# M55M1 register map
File version: 1.0
Registers are 32-bit, read-write, reset 0x0 unless marked. A register's access mark holds for its fields unless they carry their own. Offsets are from the block's base; [hi:lo] are bit positions; {n}, {i} and the like mark numbered series.

## UART0 (part 1 of 2) — UART Register Map
Base 0x4024D000
Same registers: UART1 0x4028D000, UART0_NS 0x5024D000, UART1_NS 0x5028D000
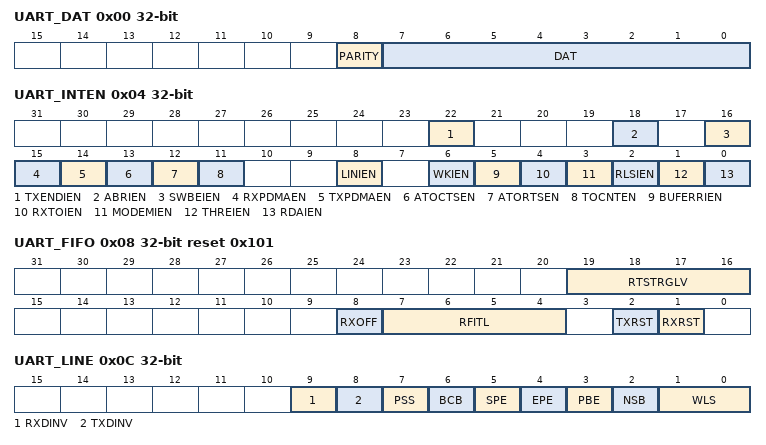
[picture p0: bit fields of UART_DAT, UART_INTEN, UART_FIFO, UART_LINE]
0x00 UART_DAT reset not defined — UART Receive/Transmit Buffer Register
  [8] PARITY — PARITY Bit Receive/Transmit Buffer. Write Operation: By writing to this bit, the PARITY bit will be stored in transmitter FIFO. If PBE (UART_LINE[3]) and PSS (UART_LINE[7]) are set, the UART controller will send out this bit follow the DAT (UART_DAT[7:0]) through the UART_TXD. Read Operation: If PBE (UART_LINE[3]) and PSS (UART_LINE[7]) are enabled, the PARITY bit can be read by this bit. Note: This bit has effect only when PBE (UART_LINE[3]) and PSS (UART_LINE[7]) are set.
  [7:0] DAT — Data Receive/Transmit Buffer. Write Operation: By writing one byte to this register, the data byte will be stored in transmitter FIFO. The UART controller will send out the data stored in transmitter FIFO top location through the UART_TXD. Read Operation: By reading this register, the UART controller will return an 8-bit data received from receiver FIFO.
0x04 UART_INTEN — UART Interrupt Enable Register
  [22] TXENDIEN — Transmitter Empty Interrupt Enable Bit. If TXENDIEN (UART_INTEN[22]) is enabled, the Transmitter Empty interrupt TXENDINT (UART_INTSTS[30]) will be generated when TXENDIF (UART_INTSTS[22]) is set (TX FIFO (UART_DAT) is empty and the STOP bit of the last byte has been transmitted).
    0=Transmitter empty interrupt Disabled; 1=Transmitter empty interrupt Enabled
  [18] ABRIEN — Auto-baud Rate Interrupt Enable Bit
    0=Auto-baud rate interrupt Disabled; 1=Auto-baud rate interrupt Enabled
  [16] SWBEIEN — Single-wire Bit Error Detection Interrupt Enable Bit. Set this bit, the Single-wire Half Duplex Bit Error Detection Interrupt SWBEINT(UART_INTSTS[24]) is generated when Single-wire Bit Error Detection SWBEIF(UART_INTSTS[16]) is set. Note: This bit is valid when FUNCSEL (UART_FUNCSEL[2:0]) is select UART Single-wire mode.
    0=Single-wire Bit Error Detect Interrupt Disabled; 1=Single-wire Bit Error Detect Interrupt Enabled
  [15] RXPDMAEN — RX PDMA Enable Bit. This bit can enable or disable RX PDMA service. Note: If RLSIEN (UART_INTEN[2]) is enabled and HWRLSINT (UART_INTSTS[26]) is set to 1, the RLS (Receive Line Status) Interrupt is caused. If RLS interrupt is caused by Break Error Flag BIF(UART_FIFOSTS[6]), Frame Error Flag FEF(UART_FIFO[5]) or Parity Error Flag PEF(UART_FIFOSTS[4]), UART PDMA receive request operation is stopped. Clear Break Error Flag BIF or Frame Error Flag FEF or Parity Error Flag PEF by writing '1' to corresponding BIF, FEF and PEF to make UART PDMA receive request operation continue.
    0=RX PDMA Disabled; 1=RX PDMA Enabled
  [14] TXPDMAEN — TX PDMA Enable Bit. Note: If RLSIEN (UART_INTEN[2]) is enabled and HWRLSINT (UART_INTSTS[26]) is set to 1, the RLS (Receive Line Status) Interrupt is caused. If RLS interrupt is caused by Break Error Flag BIF(UART_FIFOSTS[6]), Frame Error Flag FEF(UART_FIFO[5]) or Parity Error Flag PEF(UART_FIFOSTS[4]), UART PDMA transmit request operation is stopped. Clear Break Error Flag BIF or Frame Error Flag FEF or Parity Error Flag PEF by writing '1' to corresponding BIF, FEF and PEF to make UART PDMA transmit request operation continue.
    0=TX PDMA Disabled; 1=TX PDMA Enabled
  [13] ATOCTSEN — nCTS Auto-flow Control Enable Bit. Note: When nCTS auto-flow is enabled, the UART will send data to external device if nCTS input assert (UART will not send data to device until nCTS is asserted).
    0=nCTS auto-flow control Disabled; 1=nCTS auto-flow control Enabled
  [12] ATORTSEN — nRTS Auto-flow Control Enable Bit. Note: When nRTS auto-flow is enabled, if the number of bytes in the RX FIFO equals the RTSTRGLV (UART_FIFO[19:16]), the UART will de-assert nRTS signal.
    0=nRTS auto-flow control Disabled; 1=nRTS auto-flow control Enabled
  [11] TOCNTEN — Receive Buffer Time-out Counter Enable Bit
    0=Receive Buffer Time-out counter Disabled; 1=Receive Buffer Time-out counter Enabled
  [8] LINIEN — LIN Bus Interrupt Enable Bit. Note: This bit is used for LIN function mode.
    0=LIN bus interrupt Disabled; 1=LIN bus interrupt Enabled
  [6] WKIEN — Wake-up Interrupt Enable Bit
    0=Wake-up Interrupt Disabled; 1=Wake-up Interrupt Enabled
  [5] BUFERRIEN — Buffer Error Interrupt Enable Bit
    0=Buffer error interrupt Disabled; 1=Buffer error interrupt Enabled
  [4] RXTOIEN — RX Time-out Interrupt Enable Bit
    0=RX time-out interrupt Disabled; 1=RX time-out interrupt Enabled
  [3] MODEMIEN — Modem Status Interrupt Enable Bit
    0=Modem status interrupt Disabled; 1=Modem status interrupt Enabled
  [2] RLSIEN — Receive Line Status Interrupt Enable Bit
    0=Receive Line Status interrupt Disabled; 1=Receive Line Status interrupt Enabled
  [1] THREIEN — Transmit Holding Register Empty Interrupt Enable Bit
    0=Transmit holding register empty interrupt Disabled; 1=Transmit holding register empty interrupt Enabled
  [0] RDAIEN — Receive Data Available Interrupt Enable Bit
    0=Receive data available interrupt Disabled; 1=Receive data available interrupt Enabled
0x08 UART_FIFO reset 0x101 — UART FIFO Control Register
  [19:16] RTSTRGLV — nRTS Trigger Level for Auto-flow Control. Note: This field is used for auto nRTS flow control.
    0=nRTS Trigger Level is 1 byte; 1=nRTS Trigger Level is 4 bytes; 2=nRTS Trigger Level is 8 bytes; 3=nRTS Trigger Level is 14 bytes
  [8] RXOFF — Receiver Disable Bit. The receiver is disabled or not (set 1 to disable receiver). Note: This bit is used for RS-485 Normal Multi-drop mode. It should be programmed before RS485NMM (UART_ALTCTL[8]) is programmed.
    0=Receiver Enabled; 1=Receiver Disabled
  [7:4] RFITL — RX FIFO Interrupt Trigger Level. When the number of bytes in the receive FIFO equals the RFITL, the RDAIF (UART_INTSTS[0]) will be set (if RDAIEN (UART_INTEN[0]) enabled, and an interrupt will be generated).
    0=RX FIFO Interrupt Trigger Level is 1 byte; 1=RX FIFO Interrupt Trigger Level is 4 bytes; 2=RX FIFO Interrupt Trigger Level is 8 bytes; 3=RX FIFO Interrupt Trigger Level is 14 bytes
  [2] TXRST — TX Field Software Reset. When TXRST (UART_FIFO[2]) is set, all the byte in the transmit FIFO and TX internal state machine are cleared. Note 1: This bit will automatically clear at least 3 UART peripheral clock cycles. Note 2: Before setting this bit, it should wait for the TXEMPTYF (UART_FIFOSTS[28]) be set.
    0=No effect; 1=Reset the TX internal state machine and pointers
  [1] RXRST — RX Field Software Reset. When RXRST (UART_FIFO[1]) is set, all the byte in the receiver FIFO and RX internal state machine are cleared. Note 1: This bit will automatically clear at least 3 UART peripheral clock cycles. Note 2: Before setting this bit, it should wait for the RXIDLE (UART_FIFOSTS[29]) be set.
    0=No effect; 1=Reset the RX internal state machine and pointers
0x0C UART_LINE — UART Line Control Register
  [9] RXDINV — RX Data Inverted. Note 1: Before setting this bit, TXRXDIS (UART_FUNCSEL[3]) should be set then waited for TXRXACT (UART_FIFOSTS[31]) is cleared. When the configuration is done, cleared TXRXDIS (UART_FUNCSEL[3]) to activate UART controller. Note 2: This bit is valid when FUNCSEL (UART_FUNCSEL[2:0]) is select UART, LIN or RS485 function.
    0=Received data signal inverted Disabled; 1=Received data signal inverted Enabled
  [8] TXDINV — TX Data Inverted. Note 1: Before setting this bit, TXRXDIS (UART_FUNCSEL[3]) should be set then waited for TXRXACT (UART_FIFOSTS[31]) is cleared. When the configuration is done, cleared TXRXDIS (UART_FUNCSEL[3]) to activate UART controller. Note 2: This bit is valid when FUNCSEL (UART_FUNCSEL[2:0]) is select UART, LIN or RS485 function.
    0=Transmitted data signal inverted Disabled; 1=Transmitted data signal inverted Enabled
  [7] PSS — PARITY Bit Source Selection. The PARITY bit can be selected to be generated and checked automatically or by software. Note 1: This bit has effect only when PBE (UART_LINE[3]) is set. Note 2: If PSS is 0, the PARITY bit is transmitted and checked automatically. If PSS is 1, the transmitted PARITY bit value can be determined by writing PARITY (UART_DAT[8]) and the PARITY bit can be read by reading PARITY (UART_DAT[8]).
    0=PARITY bit is generated by EPE (UART_LINE[4]) and SPE (UART_LINE[5]) setting and checked automatically; 1=PARITY bit generated and checked by software
  [6] BCB — Break Control Bit. Note: When this bit is set to logic 1, the transmitted serial data output (TX) is forced to the Spacing State (logic 0). This bit acts only on TX line and has no effect on the transmitter logic.
    0=Break Control Disabled; 1=Break Control Enabled
  [5] SPE — Stick Parity Enable Bit. Note: If PBE (UART_LINE[3]) and EPE (UART_LINE[4]) are logic 1, the PARITY bit is transmitted and checked as logic 0. If PBE (UART_LINE[3]) is 1 and EPE (UART_LINE[4]) is 0 then the PARITY bit is transmitted and checked as 1.
    0=Stick parity Disabled; 1=Stick parity Enabled
  [4] EPE — Even Parity Enable Bit. Note: This bit has effect only when PBE (UART_LINE[3]) is set.
    0=Odd number of logic 1's is transmitted and checked in each word; 1=Even number of logic 1's is transmitted and checked in each word
  [3] PBE — PARITY Bit Enable Bit. Note: PARITY bit is generated on each outgoing character and is checked on each incoming data.
    0=PARITY bit generated Disabled; 1=PARITY bit generated Enabled
  [2] NSB — Number of 'STOP Bit'
    0=One 'STOP bit' is generated in the transmitted data; 1=When select 5-bit word length, 1.5 'STOP bit' is generated in the transmitted data. When select 6-, 7- and 8-bit word length, 2 'STOP bit' is generated in the transmitted data
  [1:0] WLS — Word Length Selection. This field sets UART word length.
    {v}={v+5} bits (v=0..3)
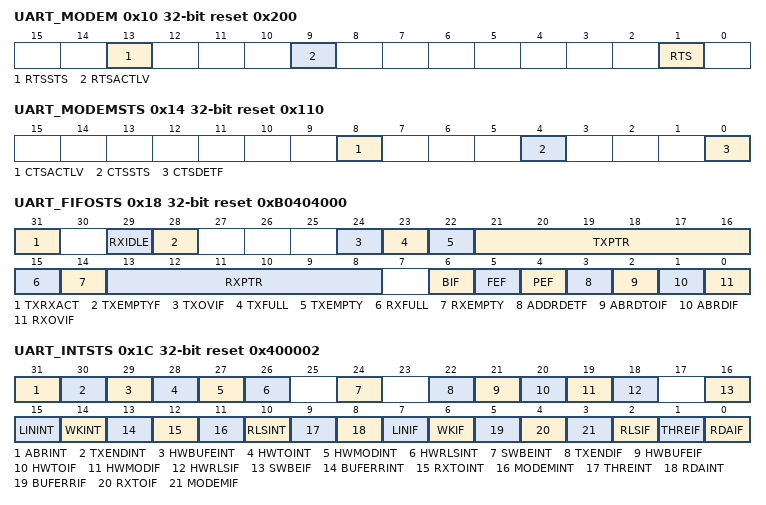
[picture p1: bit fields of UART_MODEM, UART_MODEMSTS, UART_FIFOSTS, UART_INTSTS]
0x10 UART_MODEM reset 0x200 — UART Modem Control Register
  [13] RTSSTS ro — nRTS Pin Status (Read Only). This bit mirror from nRTS pin output of voltage logic status.
    0=nRTS pin output is low level voltage logic state; 1=nRTS pin output is high level voltage logic state
  [9] RTSACTLV — nRTS Pin Active Level. This bit defines the active level state of nRTS pin output. Note 1: Refer to Figure 6.2613 and Figure 6.2614 for UART function mode. Note 2: Refer to Figure 6.2624 and Figure 6.2625 for RS-485 function mode. Note 3: Before setting this bit, TXRXDIS (UART_FUNCSEL[3]) should be set then waited for TXRXACT (UART_FIFOSTS[31]) is cleared. When the configuration is done, cleared TXRXDIS (UART_FUNCSEL[3]) to activate UART controller.
    0=nRTS pin output is high level active; 1=nRTS pin output is low level active. (Default)
  [1] RTS — nRTS Signal Control. This bit is direct control internal nRTS (Request-to-send) signal active or not, and then drive the nRTS pin output with RTSACTLV bit configuration. Note 1: The nRTS signal control bit is not effective when nRTS auto-flow control is enabled in UART function mode. Note 2: The nRTS signal control bit is not effective when RS-485 auto direction mode (AUD) is enabled in RS-485 function mode. Note 3: Single-wire mode is support this feature.
    0=nRTS signal is active; 1=nRTS signal is inactive
0x14 UART_MODEMSTS reset 0x110 — UART Modem Status Register
  [8] CTSACTLV — nCTS Pin Active Level. This bit defines the active level state of nCTS pin input. Note: Before setting this bit, TXRXDIS (UART_FUNCSEL[3]) should be set then waited for TXRXACT (UART_FIFOSTS[31]) is cleared. When the configuration is done, cleared TXRXDIS (UART_FUNCSEL[3]) to activate UART controller.
    0=nCTS pin input is high level active; 1=nCTS pin input is low level active. (Default)
  [4] CTSSTS ro — nCTS Pin Status (Read Only). This bit mirror from nCTS pin input of voltage logic status. Note: This bit echoes when UART controller peripheral clock is enabled, and nCTS multi-function port is selected.
    0=nCTS pin input is low level voltage logic state; 1=nCTS pin input is high level voltage logic state
  [0] CTSDETF — Detect nCTS State Change Flag. This bit is set whenever nCTS input has change state, and it will generate Modem interrupt to CPU when MODEMIEN (UART_INTEN[3]) is set to 1. Note: This bit can be cleared by writing '1' to it.
    0=nCTS input has not change state; 1=nCTS input has change state
0x18 UART_FIFOSTS reset 0xB0404000 — UART FIFO Status Register
  [31] TXRXACT ro — TX and RX Active Status (Read Only). This bit indicates TX and RX are active or inactive. Note: When TXRXDIS (UART_FUNCSEL[3]) is set and both TX and RX are in idle state, this bit is cleared. The UART controller cannot transmit or receive data at this moment. Otherwise this bit is set.
    0=TX and RX are inactive; 1=TX and RX are active. (Default)
  [29] RXIDLE ro — RX Idle Status (Read Only). This bit is set by hardware when RX is idle.
    0=RX is busy; 1=RX is idle. (Default)
  [28] TXEMPTYF ro — Transmitter Empty Flag (Read Only). This bit is set by hardware when TX FIFO (UART_DAT) is empty and the STOP bit of the last byte has been transmitted. Note: This bit is cleared automatically when TX FIFO is not empty or the last byte transmission has not completed.
    0=TX FIFO is not empty or the STOP bit of the last byte has been not transmitted; 1=TX FIFO is empty and the STOP bit of the last byte has been transmitted
  [24] TXOVIF — TX Overflow Error Interrupt Flag. If TX FIFO (UART_DAT) is full, an additional write to UART_DAT will cause this bit to logic 1. Note: This bit can be cleared by writing '1' to it.
    0=TX FIFO is not overflow; 1=TX FIFO is overflow
  [23] TXFULL ro — Transmitter FIFO Full (Read Only). This bit indicates TX FIFO full or not. Note: This bit is set when the number of usage in TX FIFO Buffer is equal to 16, otherwise it is cleared by hardware.
    0=TX FIFO is not full; 1=TX FIFO is full
  [22] TXEMPTY ro — Transmitter FIFO Empty (Read Only). This bit indicates TX FIFO empty or not. Note: When the last byte of TX FIFO has been transferred to Transmitter Shift Register, hardware sets this bit high. It will be cleared when writing data into UART_DAT (TX FIFO not empty).
    0=TX FIFO is not empty; 1=TX FIFO is empty
  [21:16] TXPTR ro — TX FIFO Pointer (Read Only). This field indicates the TX FIFO Buffer Pointer. When CPU writes one byte into UART_DAT, TXPTR increases one. When one byte of TX FIFO is transferred to Transmitter Shift Register, TXPTR decreases one. The Maximum value shown in TXPTR is 15. When the using level of TX FIFO Buffer equal to 16, the TXFULL bit is set to 1 and TXPTR will show 0. As one byte of TX FIFO is transferred to Transmitter Shift Register, the TXFULL bit is cleared to 0 and TXPTR will show 15.
  [15] RXFULL ro — Receiver FIFO Full (Read Only). This bit initiates RX FIFO full or not. Note: This bit is set when the number of usage in RX FIFO Buffer is equal to 16, otherwise it is cleared by hardware.
    0=RX FIFO is not full; 1=RX FIFO is full
  [14] RXEMPTY ro — Receiver FIFO Empty (Read Only). This bit initiate RX FIFO empty or not. Note: When the last byte of RX FIFO has been read by CPU, hardware sets this bit high. It will be cleared when UART receives any new data.
    0=RX FIFO is not empty; 1=RX FIFO is empty
  [13:8] RXPTR ro — RX FIFO Pointer (Read Only). This field indicates the RX FIFO Buffer Pointer. When UART receives one byte from external device, RXPTR increases one. When one byte of RX FIFO is read by CPU, RXPTR decreases one. The Maximum value shown in RXPTR is 15. When the using level of RX FIFO Buffer equal to 16, the RXFULL bit is set to 1 and RXPTR will show 0. As one byte of RX FIFO is read by CPU, the RXFULL bit is cleared to 0 and RXPTR will show 15.
  [6] BIF — Break Interrupt Flag. This bit is set to logic 1 whenever the received data input (RX) is held in the 'spacing state' (logic 0) for longer than a full word transmission time (that is, the total time of 'START bit' + data bits + parity + STOP bits). Note: This bit can be cleared by writing '1' to it.
    0=No Break interrupt is generated; 1=Break interrupt is generated
  [5] FEF — Framing Error Flag. This bit is set to logic 1 whenever the received character does not have a valid 'STOP bit' (that is, the STOP bit following the last data bit or PARITY bit is detected as logic 0). Note: This bit can be cleared by writing '1' to it.
    0=No framing error is generated; 1=Framing error is generated
  [4] PEF — Parity Error Flag. This bit is set to logic 1 whenever the received character does not have a valid 'PARITY bit'. Note: This bit can be cleared by writing '1' to it.
    0=No parity error is generated; 1=Parity error is generated
  [3] ADDRDETF — RS-485 Address Byte Detect Flag. Note 1: This field is used for RS-485 function mode and ADDRDEN (UART_ALTCTL[15]) is set to 1 to enable Address detection mode. Note 2: This bit can be cleared by writing '1' to it.
    0=Receiver detects a data that is not an address bit (bit 9 ='0'); 1=Receiver detects a data that is an address bit (bit 9 ='1')
  [2] ABRDTOIF — Auto-baud Rate Detect Time-out Interrupt Flag. This bit is set to logic '1' in Auto-baud Rate Detect mode when the baud rate counter is overflow. Note: This bit can be cleared by writing '1' to it.
    0=Auto-baud rate counter is underflow; 1=Auto-baud rate counter is overflow
  [1] ABRDIF — Auto-baud Rate Detect Interrupt Flag. This bit is set to logic '1' when auto-baud rate detect function is finished. Note: This bit can be cleared by writing '1' to it.
    0=Auto-baud rate detect function is not finished; 1=Auto-baud rate detect function is finished
  [0] RXOVIF — RX Overflow Error Interrupt Flag. This bit is set when RX FIFO overflow. If the number of bytes of received data is greater than RX_FIFO (UART_DAT) size 16 bytes, this bit will be set. Note: This bit can be cleared by writing '1' to it.
    0=RX FIFO is not overflow; 1=RX FIFO is overflow
0x1C UART_INTSTS reset 0x400002 — UART Interrupt Status Register
  [31] ABRINT ro — Auto-baud Rate Interrupt Indicator (Read Only). This bit is set if ABRIEN (UART_INTEN[18]) and ABRIF (UART_ALTCTL[17]) are both set to 1.
    0=No Auto-baud Rate interrupt is generated; 1=The Auto-baud Rate interrupt is generated
  [30] TXENDINT ro — Transmitter Empty Interrupt Indicator (Read Only). This bit is set if TXENDIEN (UART_INTEN[22]) and TXENDIF(UART_INTSTS[22]) are both set to 1.
    0=No Transmitter Empty interrupt is generated; 1=Transmitter Empty interrupt is generated
  [29] HWBUFEINT ro — PDMA Mode Buffer Error Interrupt Indicator (Read Only). This bit is set if BUFERRIEN (UART_INTEN[5]) and HWBUFEIF (UART_INTSTS[21]) are both set to 1.
    0=No buffer error interrupt is generated when RXPDMAEN (UART_INTEN[15]) or TXPDMAEN (UART_INTEN[14]) is 1; 1=Buffer error interrupt is generated when RXPDMAEN (UART_INTEN[15]) or TXPDMAEN (UART_INTEN[14]) is 1
  [28] HWTOINT ro — PDMA Mode RX Time-out Interrupt Indicator (Read Only). This bit is set if RXTOIEN (UART_INTEN[4]) and HWTOIF(UART_INTSTS[20]) are both set to 1.
    0=No RX time-out interrupt is generated when RXPDMAEN (UART_INTEN[15]) or TXPDMAEN (UART_INTEN[14]) is 1; 1=RX time-out interrupt is generated when RXPDMAEN (UART_INTEN[15]) or TXPDMAEN (UART_INTEN[14]) is 1
  [27] HWMODINT ro — PDMA Mode MODEM Status Interrupt Indicator (Read Only). This bit is set if MODEMIEN (UART_INTEN[3]) and HWMODIF(UART_INTSTS[19]) are both set to 1.
    0=No Modem interrupt is generated when RXPDMAEN (UART_INTEN[15]) or TXPDMAEN (UART_INTEN[14]) is 1; 1=Modem interrupt is generated when RXPDMAEN (UART_INTEN[15]) or TXPDMAEN (UART_INTEN[14]) is 1
  [26] HWRLSINT ro — PDMA Mode Receive Line Status Interrupt Indicator (Read Only). This bit is set if RLSIEN (UART_INTEN[2]) and HWRLSIF(UART_INTSTS[18]) are both set to 1.
    0=No RLS interrupt is generated when RXPDMAEN (UART_INTEN[15]) or TXPDMAEN (UART_INTEN[14]) is 1; 1=RLS interrupt is generated when RXPDMAEN (UART_INTEN[15]) or TXPDMAEN (UART_INTEN[14]) is 1
  [24] SWBEINT ro — Single-wire Bit Error Detect Interrupt Indicator (Read Only). This bit is set if SWBEIEN (UART_INTEN[16]) and SWBEIF (UART_INTSTS[16]) are both set to 1.
    0=No Single-wire Bit Error Detection Interrupt generated; 1=Single-wire Bit Error Detection Interrupt generated
  [22] TXENDIF — Transmitter Empty Interrupt Flag. This bit is set when TX FIFO (UART_DAT) is empty and the STOP bit of the last byte has been transmitted (TXEMPTYF (UART_FIFOSTS[28]) is set). If TXENDIEN (UART_INTEN[22]) is enabled, the Transmitter Empty interrupt will be generated. Note: This bit is cleared automatically when TX FIFO is not empty or the last byte transmission has not completed.
    0=No transmitter empty interrupt flag is generated; 1=Transmitter empty interrupt flag is generated
  [21] HWBUFEIF ro — PDMA Mode Buffer Error Interrupt Flag (Read Only). This bit is set when the TX or RX FIFO overflows (TXOVIF (UART_FIFOSTS[24]) or RXOVIF (UART_FIFOSTS[0]) is set). When BUFERRIF (UART_INTSTS[5]) is set, the transfer maybe is not correct. If BUFERRIEN (UART_INTEN[5]) is enabled, the buffer error interrupt will be generated. Note: This bit is cleared when both TXOVIF (UART_FIFOSTS[24]]) and RXOVIF (UART_FIFOSTS[0]) are cleared.
    0=No buffer error interrupt flag is generated when RXPDMAEN (UART_INTEN[15]) or TXPDMAEN (UART_INTEN[14]) is 1; 1=Buffer error interrupt flag is generated when RXPDMAEN (UART_INTEN[15]) or TXPDMAEN (UART_INTEN[14]) is 1
  [20] HWTOIF ro — PDMA Mode RX Time-out Interrupt Flag (Read Only). This bit is set when the RX FIFO is not empty and no activities occurred in the RX FIFO and the time-out counter equal to TOIC (UART_TOUT[7:0]). If RXTOIEN (UART_INTEN[4]) is enabled, the RX time-out interrupt will be generated. Note: This bit is read only and user can read UART_DAT (RX is in active) to clear it.
    0=No RX time-out interrupt flag is generated when RXPDMAEN (UART_INTEN[15]) or TXPDMAEN (UART_INTEN[14]) is 1; 1=RX time-out interrupt flag is generated when RXPDMAEN (UART_INTEN[15]) or TXPDMAEN (UART_INTEN[14]) is 1
  [19] HWMODIF ro — PDMA Mode MODEM Interrupt Flag (Read Only). Note: This bit is read only and reset to 0 when the bit CTSDETF (UART_MODEMSTS[0]) is cleared by writing 1 on CTSDETF (UART_MODEMSTS[0]).
    0=No Modem interrupt flag is generated when RXPDMAEN (UART_INTEN[15]) or TXPDMAEN (UART_INTEN[14]) is 1; 1=Modem interrupt flag is generated when RXPDMAEN (UART_INTEN[15]) or TXPDMAEN (UART_INTEN[14]) is 1
  [18] HWRLSIF ro — PDMA Mode Receive Line Status Flag (Read Only). This bit is set when the RX receive data have parity error, frame error or break error (at least one of 3 bits, BIF (UART_FIFOSTS[6]), FEF (UART_FIFOSTS[5]) and PEF (UART_FIFOSTS[4]) is set). If RLSIEN (UART_INTEN[2]) is enabled, the RLS interrupt will be generated. Note 2: In UART function mode, this bit is read only and reset to 0 when all bits of BIF(UART_FIFOSTS[6]), FEF(UART_FIFOSTS[5]) and PEF(UART_FIFOSTS[4]) are cleared. Note 3: In RS-485 function mode, this bit is read only and reset to 0 when all bits of BIF(UART_FIFOSTS[6]), FEF(UART_FIFOSTS[5]), PEF(UART_FIFOSTS[4]) and ADDRDETF (UART_FIFOSTS[3]) are cleared.
    0=No RLS interrupt flag is generated when RXPDMAEN (UART_INTEN[15]) or TXPDMAEN (UART_INTEN[14]) is 1; 1=RLS interrupt flag is generated when RXPDMAEN (UART_INTEN[15]) or TXPDMAEN (UART_INTEN[14]) is 1
  [16] SWBEIF — Single-wire Bit Error Detection Interrupt Flag. This bit is set when the single wire bus state not equals to UART controller TX state in Single-wire mode. Note 1: This bit is active when FUNCSEL (UART_FUNCSEL[2:0]) is select UART Single-wire mode. Note 2: This bit can be cleared by writing '1' to it.
    0=No single-wire bit error detection interrupt flag is generated; 1=Single-wire bit error detection interrupt flag is generated
  [15] LININT ro — LIN Bus Interrupt Indicator (Read Only). This bit is set if LINIEN (UART_INTEN[8]) and LINIF(UART_INTSTS[7]) are both set to 1.
    0=No LIN Bus interrupt is generated; 1=The LIN Bus interrupt is generated
  [14] WKINT ro — UART Wake-up Interrupt Indicator (Read Only). This bit is set if WKIEN (UART_INTEN[6]) and WKIF (UART_INTSTS[6]) are both set to 1.
    0=No UART wake-up interrupt is generated; 1=UART wake-up interrupt is generated
  [13] BUFERRINT ro — Buffer Error Interrupt Indicator (Read Only). This bit is set if BUFERRIEN(UART_INTEN[5]) and BUFERRIF(UART_ INTSTS[5]) are both set to 1. Note: This bit is valid only when RXPDMAEN (UART_INTEN[15]) and TXPDMAEN (UART_INTEN[14]) are both 0.
    0=No buffer error interrupt is generated; 1=Buffer error interrupt is generated
  [12] RXTOINT ro — RX Time-out Interrupt Indicator (Read Only). This bit is set if RXTOIEN (UART_INTEN[4]) and RXTOIF(UART_INTSTS[4]) are both set to 1. Note: This bit is valid only when RXPDMAEN (UART_INTEN[15]) and TXPDMAEN (UART_INTEN[14]) are both 0.
    0=No RX time-out interrupt is generated; 1=RX time-out interrupt is generated
  [11] MODEMINT ro — MODEM Status Interrupt Indicator (Read Only). This bit is set if MODEMIEN(UART_INTEN[3]) and MODEMIF(UART_INTSTS[3]) are both set to 1. Note: This bit is valid only when RXPDMAEN (UART_INTEN[15]) and TXPDMAEN (UART_INTEN[14]) are both 0.
    0=No Modem interrupt is generated; 1=Modem interrupt is generated
  [10] RLSINT ro — Receive Line Status Interrupt Indicator (Read Only). This bit is set if RLSIEN (UART_INTEN[2]) and RLSIF(UART_INTSTS[2]) are both set to 1. Note: This bit is valid only when RXPDMAEN (UART_INTEN[15]) and TXPDMAEN (UART_INTEN[14]) are both 0.
    0=No RLS interrupt is generated; 1=RLS interrupt is generated
  [9] THREINT ro — Transmit Holding Register Empty Interrupt Indicator (Read Only). This bit is set if THREIEN (UART_INTEN[1]) and THREIF(UART_INTSTS[1]) are both set to 1.
    0=No THRE interrupt is generated; 1=THRE interrupt is generated
  [8] RDAINT ro — Receive Data Available Interrupt Indicator (Read Only). This bit is set if RDAIEN (UART_INTEN[0]) and RDAIF (UART_INTSTS[0]) are both set to 1.
    0=No RDA interrupt is generated; 1=RDA interrupt is generated
  [7] LINIF — LIN Bus Interrupt Flag. Note: This bit is cleared when SLVHDETF(UART_LINSTS[0]), BRKDETF(UART_LINSTS[8]), BITEF(UART_LINSTS[9]), SLVIDPEF (UART_LINSTS[2]) and SLVHEF(UART_LINSTS[1]) all are cleared and software writing '1' to LINIF(UART_INTSTS[7]).
    0=None of SLVHDETF, BRKDETF, BITEF, SLVIDPEF and SLVHEF is generated; 1=At least one of SLVHDETF, BRKDETF, BITEF, SLVIDPEF and SLVHEF is generated
  [6] WKIF ro — UART Wake-up Interrupt Flag (Read Only). This bit is set when TOUTWKF (UART_WKSTS[4]), RS485WKF (UART_WKSTS[3]), RFRTWKF (UART_WKSTS[2]), DATWKF (UART_WKSTS[1]) or CTSWKF(UART_WKSTS[0]) is set to 1. Note: This bit is cleared if all of TOUTWKF, RS485WKF, RFRTWKF, DATWKF and CTSWKF are cleared to 0 by writing 1 to the corresponding interrupt flag.
    0=No UART wake-up interrupt flag is generated; 1=UART wake-up interrupt flag is generated
  [5] BUFERRIF ro — Buffer Error Interrupt Flag (Read Only). This bit is set when the TX FIFO or RX FIFO overflows (TXOVIF (UART_FIFOSTS[24]) or RXOVIF (UART_FIFOSTS[0]) is set). When BUFERRIF (UART_INTSTS[5]) is set, the transfer is not correct. If BUFERRIEN (UART_INTEN[5]) is enabled, the buffer error interrupt will be generated. Note 1: This bit is cleared if both of RXOVIF(UART_FIFOSTS[0]) and TXOVIF(UART_FIFOSTS[24]) are cleared to 0 by writing 1 to RXOVIF(UART_FIFOSTS[0]) and TXOVIF(UART_FIFOSTS[24]). Note 2: This bit is valid only when RXPDMAEN (UART_INTEN[15]) and TXPDMAEN (UART_INTEN[14]) are both 0.
    0=No buffer error interrupt flag is generated; 1=Buffer error interrupt flag is generated
  [4] RXTOIF ro — RX Time-out Interrupt Flag (Read Only). This bit is set when the RX FIFO is not empty and no activities occurred in the RX FIFO and the time-out counter equal to TOIC (UART_TOUT[7:0]). If RXTOIEN (UART_INTEN[4]) is enabled, the RX time-out interrupt will be generated. Note 1: This bit is read only and user can read UART_DAT (RX is in active) to clear it. Note 2: This bit is valid only when RXPDMAEN (UART_INTEN[15]) and TXPDMAEN (UART_INTEN[14]) are both 0.
    0=No RX time-out interrupt flag is generated; 1=RX time-out interrupt flag is generated
  [3] MODEMIF ro — MODEM Interrupt Flag (Read Only). Note 1: This bit is read only and reset to 0 when bit CTSDETF is cleared by a write 1 on CTSDETF(UART_MODEMSTS[0]). Note 2: This bit is valid only when RXPDMAEN (UART_INTEN[15]) and TXPDMAEN (UART_INTEN[14]) are both 0.
    0=No Modem interrupt flag is generated; 1=Modem interrupt flag is generated
  [2] RLSIF ro — Receive Line Interrupt Flag (Read Only). This bit is set when the RX receive data have parity error, frame error or break error (at least one of 3 bits, BIF(UART_FIFOSTS[6]), FEF(UART_FIFOSTS[5]) and PEF(UART_FIFOSTS[4]), is set). If RLSIEN (UART_INTEN[2]) is enabled, the RLS interrupt will be generated. Note 2: This bit is read only and reset to 0 when all bits of BIF (UART_FIFOSTS[6]), FEF(UART_FIFOSTS[5]) and PEF(UART_FIFOSTS[4]) are cleared. Note 3: In RS-485 function mode, this bit is read only and reset to 0 when all bits of BIF (UART_FIFOSTS[6]), FEF(UART_FIFOSTS[5]), PEF(UART_FIFOSTS[4]) and ADDRDETF (UART_FIFOSTS[3]) are cleared. Note 4: This bit is valid only when RXPDMAEN (UART_INTEN[15]) and TXPDMAEN (UART_INTEN[14]) are both 0.
    0=No RLS interrupt flag is generated; 1=RLS interrupt flag is generated
  [1] THREIF ro — Transmit Holding Register Empty Interrupt Flag (Read Only). This bit is set when the last data of TX FIFO is transferred to Transmitter Shift Register. If THREIEN (UART_INTEN[1]) is enabled, the THRE interrupt will be generated. Note: This bit is read only and will be cleared when writing data into UART_DAT (TX FIFO is not empty).
    0=No THRE interrupt flag is generated; 1=THRE interrupt flag is generated
  [0] RDAIF ro — Receive Data Available Interrupt Flag (Read Only). When the number of bytes in the RX FIFO equals the RFITL then the RDAIF(UART_INTSTS[0]) will be set. If RDAIEN (UART_INTEN[0]) is enabled, the RDA interrupt will be generated. Note: This bit is read only and will be cleared when the number of unread bytes of RX FIFO drops below the threshold level (RFITL(UART_FIFO[7:4]).
    0=No RDA interrupt flag is generated; 1=RDA interrupt flag is generated

## UART2 (part 1 of 2) — UART Register Map
Base 0x4024E000
Registers as UART0.

## UART4 (part 1 of 2) — UART Register Map
Base 0x4024F000
Registers as UART0.

## UART6 (part 1 of 2) — UART Register Map
Base 0x40250000
Registers as UART0.

## UART8 (part 1 of 2) — UART Register Map
Base 0x40251000
Registers as UART0.

## UART3 (part 1 of 2) — UART Register Map
Base 0x4028E000
Registers as UART0.

## UART5 (part 1 of 2) — UART Register Map
Base 0x4028F000
Registers as UART0.

## UART7 (part 1 of 2) — UART Register Map
Base 0x40290000
Registers as UART0.

## UART9 (part 1 of 2) — UART Register Map
Base 0x40291000
Registers as UART0.

## UART2_NS (part 1 of 2) — UART Register Map
Base 0x5024E000
Registers as UART0.

## UART4_NS (part 1 of 2) — UART Register Map
Base 0x5024F000
Registers as UART0.

## UART6_NS (part 1 of 2) — UART Register Map
Base 0x50250000
Registers as UART0.

## UART8_NS (part 1 of 2) — UART Register Map
Base 0x50251000
Registers as UART0.

## UART3_NS (part 1 of 2) — UART Register Map
Base 0x5028E000
Registers as UART0.

## UART5_NS (part 1 of 2) — UART Register Map
Base 0x5028F000
Registers as UART0.

## UART7_NS (part 1 of 2) — UART Register Map
Base 0x50290000
Registers as UART0.

## UART9_NS (part 1 of 2) — UART Register Map
Base 0x50291000
Registers as UART0.
